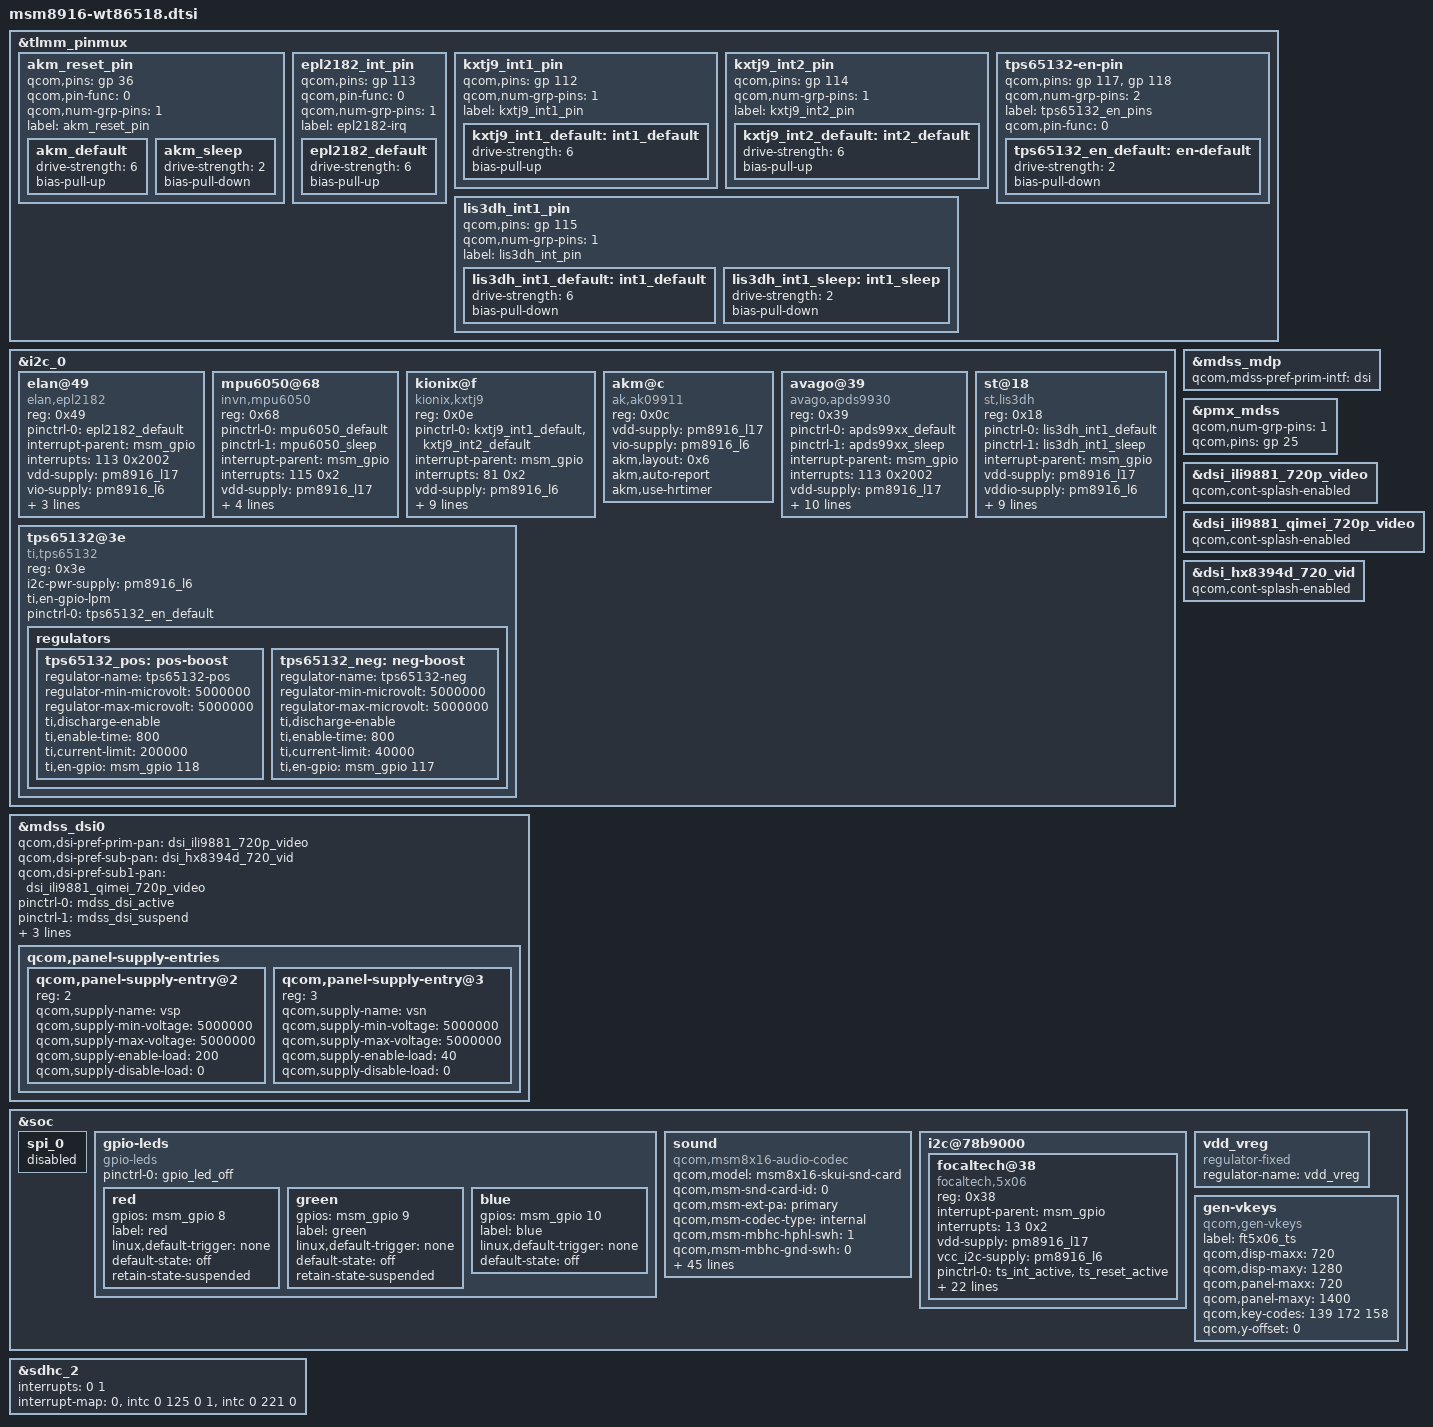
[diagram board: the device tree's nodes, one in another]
/* Copyright (c) 2014, The Linux Foundation. All rights reserved.
 *
 * This program is free software; you can redistribute it and/or modify
 * it under the terms of the GNU General Public License version 2 and
 * only version 2 as published by the Free Software Foundation.
 *
 * This program is distributed in the hope that it will be useful,
 * but WITHOUT ANY WARRANTY; without even the implied warranty of
 * MERCHANTABILITY or FITNESS FOR A PARTICULAR PURPOSE.  See the
 * GNU General Public License for more details.
 */
                                              
#include "dsi-panel-ili9881-720p-video.dtsi"
#include "dsi-panel-ili9881-qimei-720p-video.dtsi"
#include "dsi-panel-hx8394d-720p-video.dtsi"
#include "msm-pm8916-wt86518.dtsi"
#include "msm8916-camera-sensor-wt86518.dtsi"

&tlmm_pinmux {
	akm_reset_pin {
		qcom,pins = <&gp 36>;
		qcom,pin-func = <0>;
		qcom,num-grp-pins = <1>;
		label = "akm_reset_pin";
		akm_default: akm_default {
			drive-strength = <6>;
			bias-pull-up;
		};
		akm_sleep: akm_sleep {
			drive-strength = <2>;
			bias-pull-down;
		};
	};

	epl2182_int_pin {
		qcom,pins = <&gp 113>;
		qcom,pin-func = <0>;
		qcom,num-grp-pins = <1>;
		label = "epl2182-irq";
		epl2182_default: epl2182_default {
		drive-strength = <6>;
		bias-pull-up;
		};
	};
	kxtj9_int1_pin {
		qcom,pins = <&gp 112>;
		qcom,num-grp-pins = <1>;
		label = "kxtj9_int1_pin";
		kxtj9_int1_default: int1_default {
			  drive-strength = <6>;
			  bias-pull-up;
		};
	};
	kxtj9_int2_pin {
		qcom,pins = <&gp 114>;
		qcom,num-grp-pins = <1>;
		label = "kxtj9_int2_pin";
		kxtj9_int2_default: int2_default {
			  drive-strength = <6>;
			  bias-pull-up;
		};
	};		
	
	lis3dh_int1_pin {
		qcom,pins = <&gp 115>;
		qcom,num-grp-pins = <1>;
		label = "lis3dh_int_pin";
		lis3dh_int1_default: int1_default {
			drive-strength = <6>;
			bias-pull-down;
		};
		lis3dh_int1_sleep: int1_sleep {
			drive-strength = <2>;
			bias-pull-down;
		};
	};

	tps65132-en-pin {
		qcom,pins = <&gp 117>, <&gp 118>;
		qcom,num-grp-pins = <2>;
		label = "tps65132_en_pins";
		qcom,pin-func = <0>;

		tps65132_en_default: en-default {
			drive-strength = <2>;
			bias-pull-down;
		};
	};
};

&i2c_0 { /* BLSP1 QUP2 */
	elan@49 { 
		compatible = "elan,epl2182";
		reg = <0x49>;
		pinctrl-names = "default";
		pinctrl-0 = <&epl2182_default>;
		interrupt-parent = <&msm_gpio>;
		interrupts = <113 0x2002>;
		vdd-supply = <&pm8916_l17>;
		vio-supply = <&pm8916_l6>;
		epl2182,irq-gpio = <&msm_gpio 113 0x2002>;
		epl2182,prox_th_min = <1900>;
		epl2182,prox_th_max = <2600>;
	};
	mpu6050@68 {
		compatible = "invn,mpu6050";
		reg = <0x68>;
		pinctrl-names = "mpu_default","mpu_sleep";
		pinctrl-0 = <&mpu6050_default>;
		pinctrl-1 = <&mpu6050_sleep>;
		interrupt-parent = <&msm_gpio>;
		interrupts = <115 0x2>;
		vdd-supply = <&pm8916_l17>;
		vlogic-supply = <&pm8916_l16>;
		vi2c-supply = <&pm8916_l6>;
		invn,gpio-int = <&msm_gpio 115 0x2>;
		invn,place = "Portrait Up Back Side";
	};
	kionix@f {
	       compatible = "kionix,kxtj9";
		reg = <0x0e>;
		pinctrl-names = "default";
		pinctrl-0 = <&kxtj9_int1_default &kxtj9_int2_default>;
		interrupt-parent = <&msm_gpio>;
		interrupts = <81 0x2>;
		vdd-supply = <&pm8916_l6>;
		vio-supply = <&pm8916_l6>;
		kionix,min-interval = <10>;
		kionix,init-interval = <200>;
		kionix,axis-map-x = <1>;
		kionix,axis-map-y = <0>;
		kionix,axis-map-z = <2>;
		kionix,g-range = <2>;
		kionix,negate-z;
		kionix,res-12bit;
	 };
	akm@c {
		compatible = "ak,ak09911";
		reg = <0x0c>;
		vdd-supply = <&pm8916_l17>;
		vio-supply = <&pm8916_l6>;
		akm,layout = <0x6>;
		akm,auto-report;
		akm,use-hrtimer;
	};

	avago@39 {
		compatible = "avago,apds9930";
		reg = <0x39>;
		pinctrl-names = "default","sleep";
		pinctrl-0 = <&apds99xx_default>;
		pinctrl-1 = <&apds99xx_sleep>;
		interrupt-parent = <&msm_gpio>;
		interrupts = <113 0x2002>;
		vdd-supply = <&pm8916_l17>;
		vio-supply = <&pm8916_l6>;
		avago,irq-gpio = <&msm_gpio 113 0x2002>;
		avago,ps-threshold = <600>;
		avago,ps-hysteresis-threshold = <500>;
		avago,ps-pulse = <8>;
		avago,ps-pgain = <0>;
		avago,als-B = <186>;
		avago,als-C = <75>;
		avago,als-D = <129>;
		avago,ga-value = <313>;
	};

	st@18 {
		compatible = "st,lis3dh";
		reg = <0x18>;
		pinctrl-names = "lis3dh_default","lis3dh_sleep";
		pinctrl-0 = <&lis3dh_int1_default>;
		pinctrl-1 = <&lis3dh_int1_sleep>;
		interrupt-parent = <&msm_gpio>;
		vdd-supply = <&pm8916_l17>;
		vddio-supply = <&pm8916_l6>;
		st,min-interval = <5>;
		st,init-interval = <200>;
		st,axis-map-x = <0>;
		st,axis-map-y = <1>;
		st,axis-map-z = <2>;
		st,g-range = <2>;
		st,gpio-int1 = <&msm_gpio 115 0x2002>;
		st,negate-x;
		st,negate-y;
	};

	tps65132@3e {
		compatible = "ti,tps65132";
		reg = <0x3e>;
		i2c-pwr-supply = <&pm8916_l6>;
		ti,en-gpio-lpm;
		pinctrl-names = "default";
		pinctrl-0 = <&tps65132_en_default>;

		regulators {
			tps65132_pos: pos-boost {
				regulator-name = "tps65132-pos";
				regulator-min-microvolt = <5000000>;
				regulator-max-microvolt = <5000000>;
				ti,discharge-enable;
				ti,enable-time = <800>;
				ti,current-limit = <200000>;
				ti,en-gpio = <&msm_gpio 118 0>;
			};

			tps65132_neg: neg-boost {
				regulator-name = "tps65132-neg";
				regulator-min-microvolt = <5000000>;
				regulator-max-microvolt = <5000000>;
				ti,discharge-enable;
				ti,enable-time = <800>;
				ti,current-limit = <40000>;
				ti,en-gpio = <&msm_gpio 117 0>;
			};
		};
	};

};

&mdss_mdp {
	qcom,mdss-pref-prim-intf = "dsi";
};

&pmx_mdss {
	qcom,num-grp-pins = <1>;
	qcom,pins = <&gp 25>;
};

&mdss_dsi0 {
	qcom,dsi-pref-prim-pan = <&dsi_ili9881_720p_video>;
	qcom,dsi-pref-sub-pan = <&dsi_hx8394d_720_vid>;
	qcom,dsi-pref-sub1-pan = <&dsi_ili9881_qimei_720p_video>;
	pinctrl-names = "mdss_default", "mdss_sleep";
	pinctrl-0 = <&mdss_dsi_active>;
	pinctrl-1 = <&mdss_dsi_suspend>;

	qcom,platform-reset-gpio = <&msm_gpio 25 0>;
        vsp-supply = <&tps65132_pos>;
        vsn-supply = <&tps65132_neg>;
        qcom,panel-supply-entries {
		#address-cells = <1>;
		#size-cells = <0>;

            qcom,panel-supply-entry@2 {
                reg = <2>;
                qcom,supply-name = "vsp";
                qcom,supply-min-voltage = <5000000>;
                qcom,supply-max-voltage = <5000000>;
                qcom,supply-enable-load = <200>;
                qcom,supply-disable-load = <0>;
            };

            qcom,panel-supply-entry@3 {
                reg = <3>;
                qcom,supply-name = "vsn";
                qcom,supply-min-voltage = <5000000>;
                qcom,supply-max-voltage = <5000000>;
                qcom,supply-enable-load = <40>;
                qcom,supply-disable-load = <0>;
            };
        };


};

&dsi_ili9881_720p_video {
    qcom,cont-splash-enabled;
};

&dsi_ili9881_qimei_720p_video {
    qcom,cont-splash-enabled;
};

&dsi_hx8394d_720_vid {
    qcom,cont-splash-enabled;
};

&soc {
	spi_0 {
		status = "disabled";
	};

	gpio-leds {
		compatible = "gpio-leds";
		status = "okay";
		pinctrl-names = "default";
		pinctrl-0 = <&gpio_led_off>;

		red {
			gpios = <&msm_gpio 8 0>;
			label = "red";
			linux,default-trigger = "none";
			default-state = "off";
			retain-state-suspended;
		};

		green {
			gpios = <&msm_gpio 9 0>;
			label = "green";
			linux,default-trigger = "none";
			default-state = "off";
			retain-state-suspended;
		};

		blue {
			gpios = <&msm_gpio 10 0>;
			label = "blue";
			linux,default-trigger = "none";
			default-state = "off";
		};
	};

	sound {
		compatible = "qcom,msm8x16-audio-codec";
		qcom,model = "msm8x16-skui-snd-card";
		qcom,msm-snd-card-id = <0>;
		qcom,msm-ext-pa = "primary";
		qcom,msm-codec-type = "internal";
		qcom,msm-mbhc-hphl-swh = <1>;
		qcom,msm-mbhc-gnd-swh = <0>;
		qcom,msm-hs-micbias-type = "internal";
		qcom,audio-routing =
			"RX_BIAS", "MCLK",
			"SPK_RX_BIAS", "MCLK",
			"INT_LDO_H", "MCLK",
			"MIC BIAS Internal1", "Handset Mic",
			"MIC BIAS Internal2", "Headset Mic",
			"MIC BIAS Internal1", "Secondary Mic",
			"AMIC1", "MIC BIAS Internal1",
			"AMIC2", "MIC BIAS Internal2",
			"AMIC3", "MIC BIAS Internal1";
		pinctrl-names = "cdc_lines_act",
				"cdc_lines_sus";
		pinctrl-0 = <&cdc_pdm_lines_act>;
		pinctrl-1 = <&cdc_pdm_lines_sus>;
		asoc-platform = <&pcm0>, <&pcm1>, <&voip>, <&voice>,
				<&loopback>, <&compress>, <&hostless>,
				<&afe>, <&lsm>, <&routing>, <&lpa>;
		asoc-platform-names = "msm-pcm-dsp.0", "msm-pcm-dsp.1",
				"msm-voip-dsp", "msm-pcm-voice", "msm-pcm-loopback",
				"msm-compress-dsp", "msm-pcm-hostless", "msm-pcm-afe",
				"msm-lsm-client", "msm-pcm-routing", "msm-pcm-lpa";
		asoc-cpu = <&dai_pri_auxpcm>, <&dai_hdmi>,
				<&dai_mi2s0>, <&dai_mi2s1>, <&dai_mi2s2>, <&dai_mi2s3>,
				<&sb_0_rx>, <&sb_0_tx>, <&sb_1_rx>, <&sb_1_tx>,
				<&sb_3_rx>, <&sb_3_tx>, <&sb_4_rx>, <&sb_4_tx>,
				<&bt_sco_rx>, <&bt_sco_tx>, <&bt_a2dp_rx>,
				<&int_fm_rx>, <&int_fm_tx>,
				<&afe_pcm_rx>, <&afe_pcm_tx>, <&afe_proxy_rx>,
				<&afe_proxy_tx>, <&incall_record_rx>,
				<&incall_record_tx>, <&incall_music_rx>,
				<&incall_music_2_rx>;
		asoc-cpu-names = "msm-dai-q6-auxpcm.1", "msm-dai-q6-hdmi.8",
				"msm-dai-q6-mi2s.0", "msm-dai-q6-mi2s.1",
				"msm-dai-q6-mi2s.2", "msm-dai-q6-mi2s.3",
				"msm-dai-q6-dev.16384", "msm-dai-q6-dev.16385",
				"msm-dai-q6-dev.16386", "msm-dai-q6-dev.16387",
				"msm-dai-q6-dev.16390", "msm-dai-q6-dev.16391",
				"msm-dai-q6-dev.16392", "msm-dai-q6-dev.16393",
				"msm-dai-q6-dev.12288", "msm-dai-q6-dev.12289",
				"msm-dai-q6-dev.12290", "msm-dai-q6-dev.12292",
				"msm-dai-q6-dev.12293",	"msm-dai-q6-dev.224",
				"msm-dai-q6-dev.225", "msm-dai-q6-dev.241",
				"msm-dai-q6-dev.240", "msm-dai-q6-dev.32771",
				"msm-dai-q6-dev.32772", "msm-dai-q6-dev.32773",
				"msm-dai-q6-dev.32770";
		asoc-codec = <&stub_codec>, <&pm8916_tombak_dig>;
		asoc-codec-names = "msm-stub-codec.1", "tombak_codec";
	};

	i2c@78b9000 { /* BLSP1 QUP5 */
		focaltech@38 {
			compatible = "focaltech,5x06";
			reg = <0x38>;
			interrupt-parent = <&msm_gpio>;
			interrupts = <13 0x2>;
			vdd-supply = <&pm8916_l17>;
			vcc_i2c-supply = <&pm8916_l6>;
			/* pins used by touchscreen */
			pinctrl-names = "pmx_ts_active","pmx_ts_suspend";
			pinctrl-0 = <&ts_int_active &ts_reset_active>;
			pinctrl-1 = <&ts_int_suspend &ts_reset_suspend>;
			focaltech,name = "ft6436";
			focaltech,family-id = <0x36>;
			focaltech,reset-gpio = <&msm_gpio 12 0x0>;
			focaltech,irq-gpio = <&msm_gpio 13 0x2>;
			focaltech,display-coords = <0 0 720 1280>;
			focaltech,panel-coords = <0 0 720 1280>;
			focaltech,button-map= <139 102 158>;
			focaltech,no-force-update;
			focaltech,i2c-pull-up;
			focaltech,group-id = <1>;
			focaltech,hard-reset-delay-ms = <20>;
			focaltech,soft-reset-delay-ms = <200>;
			focaltech,num-max-touches = <5>;
			focaltech,fw-delay-aa-ms = <30>;
			focaltech,fw-delay-55-ms = <30>;
			focaltech,fw-upgrade-id1 = <0x79>;
			focaltech,fw-upgrade-id2 = <0x18>;
			focaltech,fw-delay-readid-ms = <10>;
			focaltech,fw-delay-era-flsh-ms = <2000>;
			focaltech,fw-auto-cal;
			focaltech,ignore-id-check;
		};
	};

	vdd_vreg: vdd_vreg {
		compatible = "regulator-fixed";
		status = "ok";
		regulator-name = "vdd_vreg";
	};

	gen-vkeys {
		compatible = "qcom,gen-vkeys";
		label = "ft5x06_ts";
		qcom,disp-maxx = <720>;
		qcom,disp-maxy = <1280>;
		qcom,panel-maxx = <720>;
		qcom,panel-maxy = <1400>;
		qcom,key-codes = <139 172 158>;
		qcom,y-offset = <0>;
	};

};

&sdhc_2 {
	/* qcom,nonremovable; */

	interrupts = <0 1>;
	interrupt-map = <0 &intc 0 125 0
		1 &intc 0 221 0>;
	interrupt-names = "hc_irq", "pwr_irq";
	/delete-property/ cd-gpios;
};
